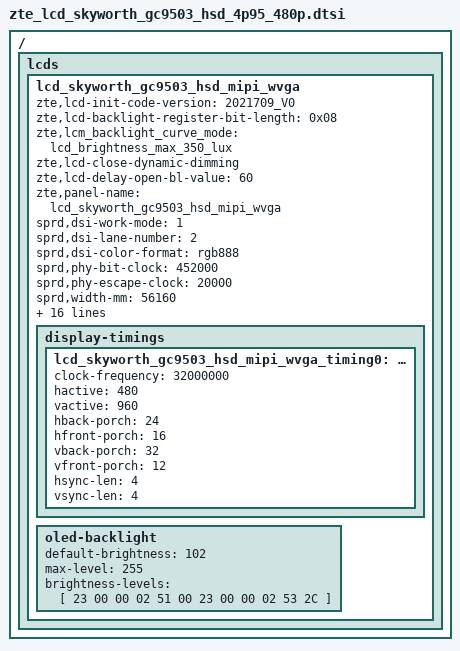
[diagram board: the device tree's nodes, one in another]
/ { lcds {
	lcd_skyworth_gc9503_hsd_mipi_wvga: lcd_skyworth_gc9503_hsd_mipi_wvga {
		zte,lcd-init-code-version = "2021709_V0";
		zte,lcd-backlight-register-bit-length = <0x08>;
		zte,lcm_backlight_curve_mode = "lcd_brightness_max_350_lux";
		zte,lcd-close-dynamic-dimming;
		zte,lcd-delay-open-bl-value = <60>;

		zte,panel-name = "lcd_skyworth_gc9503_hsd_mipi_wvga";

		sprd,dsi-work-mode = <1>; /* video burst mode*/
		sprd,dsi-lane-number = <2>;
		sprd,dsi-color-format = "rgb888";

		sprd,phy-bit-clock = <452000>;	/* kbps */
		sprd,phy-escape-clock = <20000>;/* kHz */

		sprd,width-mm = <56160>;
		sprd,height-mm = <112320>;

		sprd,esd-check-enable = <0>;/* 0:close , 1:open */
		sprd,esd-check-mode = <1>;/* 0:REG ,1:TE  */
		sprd,esd-check-period = <1000>;
		sprd,esd-check-register = <0x0A>;
		sprd,esd-check-value = <0x9C>;
		sprd,reset-on-sequence = <1 5>, <0 5>, <1 120>;
		sprd,reset-off-sequence = <0 0>, <0 0>, <1 120>;

		sprd,initial-command = [
39 00 00 06 f0 55 aa 52 08 00
39 00 00 03 f6 5a 87
39 00 00 02 c1 3f
39 00 00 02 c2 0e
39 00 00 02 c6 f8
39 00 00 02 c9 10
39 00 00 02 cd 25
39 00 00 02 f8 8a
39 00 00 02 ac 65
39 00 00 02 71 48
39 00 00 02 72 48
39 00 00 03 73 00 44
39 00 00 02 97 ee
39 00 00 02 83 93
39 00 00 02 a7 47
39 00 00 02 a0 cc
39 00 00 04 87 04 03 66
39 00 00 05 fa 8f 00 00 04
39 00 00 02 a3 22
39 00 00 04 fd 28 3c 00
39 00 00 02 9a c0
39 00 00 02 9b 80
39 00 00 03 82 58 58
39 00 00 02 b1 10
39 00 00 03 7a 08 13
39 00 00 03 7b 08 13
39 00 00 21 6d 1e 1e 1e 1e 0c 0a 10 0e 02 08 1e 1e 1e 1e 1e 1e 1e 1e 1e 1e 1e 1e 07 01 0d 0f 09 0b 1e 1e 1e 1e
39 00 00 11 64 38 04 03 c3 03 03 38 03 03 c4 03 03 1a 7a 1a 7a
39 00 00 11 65 38 02 03 bd 03 03 38 01 03 be 03 03 1a 7a 1a 7a
39 00 00 11 66 30 00 03 bf 03 03 30 01 03 c0 03 03 1a 7a 1a 7a
39 00 00 11 67 30 02 03 c1 03 03 30 03 03 c2 03 03 1a 7a 1a 7a
39 00 00 09 60 38 08 01 7a 38 07 01 7a
39 00 00 09 63 38 06 01 7a 38 05 01 7a
39 00 00 08 69 12 11 12 11 44 22 08
39 00 00 02 6b 07
39 00 00 35 d1 00 00 00 05 00 1b 00 26 00 30 00 42 00 64 00 85 00 c0 01 2a 01 70 01 ca 02 0d 02 0f 02 48 02 82 02 a0 02 c8 02 de 02 fa 03 0c 03 25 03 34 03 44 03 66 03 ff
39 00 00 35 d2 00 00 00 05 00 1b 00 26 00 30 00 42 00 64 00 85 00 c0 01 2a 01 70 01 ca 02 0d 02 0f 02 48 02 82 02 a0 02 c8 02 de 02 fa 03 0c 03 25 03 34 03 44 03 66 03 ff
39 00 00 35 d3 00 00 00 05 00 1b 00 26 00 30 00 42 00 64 00 85 00 c0 01 2a 01 70 01 ca 02 0d 02 0f 02 48 02 82 02 a0 02 c8 02 de 02 fa 03 0c 03 25 03 34 03 44 03 66 03 ff
39 00 00 35 d4 00 00 00 05 00 1b 00 26 00 30 00 42 00 64 00 85 00 c0 01 2a 01 70 01 ca 02 0d 02 0f 02 48 02 82 02 a0 02 c8 02 de 02 fa 03 0c 03 25 03 34 03 44 03 66 03 ff
39 00 00 35 d5 00 00 00 05 00 1b 00 26 00 30 00 42 00 64 00 85 00 c0 01 2a 01 70 01 ca 02 0d 02 0f 02 48 02 82 02 a0 02 c8 02 de 02 fa 03 0c 03 25 03 34 03 44 03 66 03 ff
39 00 00 35 d6 00 00 00 05 00 1b 00 26 00 30 00 42 00 64 00 85 00 c0 01 2a 01 70 01 ca 02 0d 02 0f 02 48 02 82 02 a0 02 c8 02 de 02 fa 03 0c 03 25 03 34 03 44 03 66 03 ff
23 64 00 02 11 00
39 00 00 03 B8 00 02
23 00 00 02 51 00
23 00 00 02 53 2C
23 00 00 02 55 01
23 0A 00 02 29 00
			];
		sprd,sleep-in-command = [
				23 14 00 02 6C 60
				23 00 00 02 B1 00
				39 14 00 05 FA 7F 00 00 00
				23 0a 00 02 6c 50
				23 32 00 02 28 00
				23 78 00 02 10 00
				39 00 00 06 F0 55 aa 52 08 00
				23 00 00 02 c2 ce
				23 00 00 02 c3 cd
				23 00 00 02 c6 fc
				23 00 00 02 c5 03
				23 00 00 02 cd 64
				23 00 00 02 c4 ff
				23 00 00 02 c9 cd
				39 00 00 03 F6 5a 87
				39 00 00 04 Fd aa aa 0a
				39 00 00 03 Fe 6a 0a
				39 00 00 03 78 2a aa
				39 00 00 03 92 17 08
				39 00 00 03 77 aa 2a
				39 00 00 03 76 aa aa
				23 00 00 02 84 00
				39 00 00 03 78 2b ba
				23 00 00 02 89 73
				23 00 00 02 88 3A
				23 00 00 02 85 B0
				39 00 00 03 76 eb aa
				23 00 00 02 94 80
				39 00 00 04 87 04 07 30
				23 00 00 02 93 27
				23 00 00 02 af 02
			];
		sprd,esd-special-command = [
				39 00 00 06 F0 55 AA 52 08 00
				39 00 00 03 F6 5A 87
				23 00 00 02 C1 3F
				23 00 00 02 C2 07
				23 00 00 02 C6 F8
				23 00 00 02 C9 10
				23 00 00 02 CD 25
				39 00 00 05 86 99 A3 A3 51
				39 00 00 04 87 04 03 66
				23 00 00 02 F8 8A
				23 00 00 02 AC 65
				23 00 00 02 A7 47
				23 00 00 02 A0 FF
				39 00 00 05 FA 08 08 00 04
				23 00 00 02 A3 22
				39 00 00 04 FD 3C 3C 00
				23 00 00 02 71 48
				23 00 00 02 72 48
				23 00 00 02 97 EE
				23 00 00 02 B1 10
				39 00 00 03 7A 13 1A
				39 00 00 03 7B 13 1A
				39 00 00 21 6D 1E 1F 08 02 1E 00 1D 0E 10 0A 0C 1E 1E 1E 1E
				1E 1E 1E 1E 1E 1E 0B 09 0F 0D 1D 00 1E 07 01 1F 1E
				39 00 00 11 64 38 08 03 bf 03 03 38 07 03 c0 03 03 2E 7A 2E 7A
				39 00 00 11 65 38 06 03 c1 03 03 38 05 03 c2 03 03 2E 7A 2E 7A
				39 00 00 11 66 38 04 03 c3 03 03 38 03 03 c4 03 03 2E 7A 2E 7A
				39 00 00 11 67 38 02 03 c5 03 03 38 01 03 c6 03 03 2E 7A 2E 7A
				39 00 00 09 60 38 0A 2E 7A 38 09 2E 7A
				39 00 00 09 63 38 08 2E 7A 38 07 2E 7A
				39 00 00 08 69 04 22 14 22 44 22 08
				23 00 00 02 6B 07
				23 00 00 02 38 00
				23 00 00 02 11 00
				23 00 00 02 29 00
				23 00 00 02 BA 00
			];

		sprd,sleep-out-command = [
			13 78 00 01 11
			13 64 00 01 29
			];

		display-timings {
			lcd_skyworth_gc9503_hsd_mipi_wvga_timing0: timing0 {
			clock-frequency = <32000000>;
			hactive = <480>;
			vactive = <960>;
			hback-porch = <24>;
			hfront-porch = <16>;
			vback-porch = <32>;
			vfront-porch = <12>;
			hsync-len = <4>;
			vsync-len = <4>;
			};
		};
		oled-backlight {
			default-brightness = <102>;
			max-level = <255>;
			brightness-levels = [
				23 00 00 02 51 00
				23 00 00 02 53 2C
			];
		};
	};
};};

